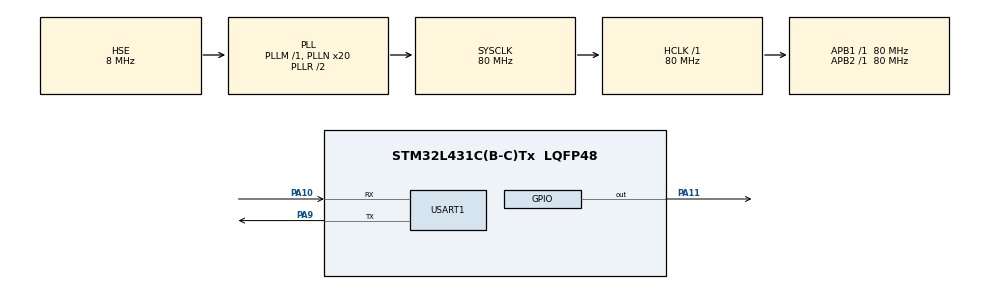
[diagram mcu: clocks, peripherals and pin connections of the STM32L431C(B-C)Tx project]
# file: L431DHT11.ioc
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Mcu.Family=STM32L4
Mcu.Name=STM32L431C(B-C)Tx
Mcu.Package=LQFP48
NVIC.PriorityGroup=NVIC_PRIORITYGROUP_4
PA10.Mode=Asynchronous
PA10.Signal=USART1_RX
PA11.Signal=GPIO_Output
PA9.Mode=Asynchronous
PA9.Signal=USART1_TX
PH0-OSC_IN\ (PH0).Mode=HSE-External-Oscillator
PH0-OSC_IN\ (PH0).Signal=RCC_OSC_IN
PH1-OSC_OUT\ (PH1).Mode=HSE-External-Oscillator
PH1-OSC_OUT\ (PH1).Signal=RCC_OSC_OUT
ProjectManager.HeapSize=0x200
ProjectManager.StackSize=0x400
ProjectManager.TargetToolchain=MDK-ARM V5.32
RCC.ADCFreq_Value=32000000
RCC.AHBFreq_Value=80000000
RCC.APB1Freq_Value=80000000
RCC.APB1TimFreq_Value=80000000
RCC.APB2Freq_Value=80000000
RCC.APB2TimFreq_Value=80000000
RCC.CortexFreq_Value=80000000
RCC.HCLKFreq_Value=80000000
RCC.HSE_VALUE=8000000
RCC.HSI48_VALUE=48000000
RCC.HSI_VALUE=16000000
RCC.LSE_VALUE=32768
RCC.MSI_VALUE=4000000
RCC.PLLN=20
RCC.PLLSourceVirtual=RCC_PLLSOURCE_HSE
RCC.SYSCLKFreq_VALUE=80000000
RCC.SYSCLKSource=RCC_SYSCLKSOURCE_PLLCLK
RCC.VCOOutputFreq_Value=160000000
TIM2.Period=65535
TIM2.Prescaler=80-1
USART1.VirtualMode-Asynchronous=VM_ASYNC
VP_TIM2_VS_ClockSourceINT.Mode=Internal
board=custom

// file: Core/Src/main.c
/* USER CODE BEGIN Header */
/**
  ******************************************************************************
  * @file           : main.c
  * @brief          : Main program body
  ******************************************************************************
  * @attention
  *
  * Copyright (c) 2024 STMicroelectronics.
  * All rights reserved.
  *
  * This software is licensed under terms that can be found in the LICENSE file
  * in the root directory of this software component.
  * If no LICENSE file comes with this software, it is provided AS-IS.
  *
  ******************************************************************************
  */
/* USER CODE END Header */
#include "main.h"
#include "tim.h"
#include "usart.h"
#include "gpio.h"

/* USER CODE BEGIN Includes */
#include <stdio.h>
/* USER CODE END Includes */

/* USER CODE BEGIN PV */

int fputc(int ch,FILE *f)
{
    HAL_UART_Transmit(&huart1,(uint8_t*)&ch,1,0xFFFF);
    return ch;
}
/* USER CODE END PV */

void SystemClock_Config(void);

int main(void)
{

  /* MCU Configuration--------------------------------------------------------*/

  /* Reset of all peripherals, Initializes the Flash interface and the Systick. */
  HAL_Init();

  /* Configure the system clock */
  SystemClock_Config();

  /* Initialize all configured peripherals */
  MX_GPIO_Init();
  MX_USART1_UART_Init();
  MX_TIM2_Init();
  /* USER CODE BEGIN 2 */
printf("Hello World");
  /* USER CODE END 2 */

  /* Infinite loop */
  /* USER CODE BEGIN WHILE */
  while (1)
  {
	HAL_GPIO_TogglePin(GPIOC, GPIO_PIN_13);
		HAL_Delay(200);
		DH11_Task( );
		HAL_Delay(1000);
    /* USER CODE END WHILE */

  }
}

void SystemClock_Config(void)
{
  RCC_OscInitTypeDef RCC_OscInitStruct = {0};
  RCC_ClkInitTypeDef RCC_ClkInitStruct = {0};

  /** Configure the main internal regulator output voltage
  */
  if (HAL_PWREx_ControlVoltageScaling(PWR_REGULATOR_VOLTAGE_SCALE1) != HAL_OK)
  {
    Error_Handler();
  }

  /** Initializes the RCC Oscillators according to the specified parameters
  * in the RCC_OscInitTypeDef structure.
  */
  RCC_OscInitStruct.OscillatorType = RCC_OSCILLATORTYPE_HSE;
  RCC_OscInitStruct.HSEState = RCC_HSE_ON;
  RCC_OscInitStruct.PLL.PLLState = RCC_PLL_ON;
  RCC_OscInitStruct.PLL.PLLSource = RCC_PLLSOURCE_HSE;
  RCC_OscInitStruct.PLL.PLLM = 1;
  RCC_OscInitStruct.PLL.PLLN = 20;
  RCC_OscInitStruct.PLL.PLLP = RCC_PLLP_DIV7;
  RCC_OscInitStruct.PLL.PLLQ = RCC_PLLQ_DIV2;
  RCC_OscInitStruct.PLL.PLLR = RCC_PLLR_DIV2;
  if (HAL_RCC_OscConfig(&RCC_OscInitStruct) != HAL_OK)
  {
    Error_Handler();
  }

  /** Initializes the CPU, AHB and APB buses clocks
  */
  RCC_ClkInitStruct.ClockType = RCC_CLOCKTYPE_HCLK|RCC_CLOCKTYPE_SYSCLK
                              |RCC_CLOCKTYPE_PCLK1|RCC_CLOCKTYPE_PCLK2;
  RCC_ClkInitStruct.SYSCLKSource = RCC_SYSCLKSOURCE_PLLCLK;
  RCC_ClkInitStruct.AHBCLKDivider = RCC_SYSCLK_DIV1;
  RCC_ClkInitStruct.APB1CLKDivider = RCC_HCLK_DIV1;
  RCC_ClkInitStruct.APB2CLKDivider = RCC_HCLK_DIV1;

  if (HAL_RCC_ClockConfig(&RCC_ClkInitStruct, FLASH_LATENCY_4) != HAL_OK)
  {
    Error_Handler();
  }
}

void Error_Handler(void)
{
  __disable_irq();
  while (1)
  {
  }
}
